# altera_avalon_timer register map
Registers are 16-bit, read-write, reset 0x0 unless marked. A register's access mark holds for its fields unless they carry their own. Offsets are from the block's base; lines under a group give offsets from that group; [hi:lo] are bit positions; {n}, {i} and the like mark numbered series; 'fields as' and 'values as' point back to an identical list; <NAME> marks a mode.

## Memory map
0x00000000 altera_avalon_timer size 0x10

## altera_avalon_timer
Base 0x00000000
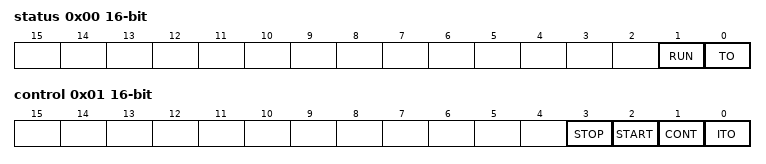
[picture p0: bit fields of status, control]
0x00 status — The status register has two defined bits. TO (timeout), RUN
  [1] RUN ro — The RUN bit reads as 1 when the internal counter is running; otherwise this bit reads as 0. The RUN bit is not changed by a write operation to the status register.
  [0] TO ro read-clears — The TO (timeout) bit is set to 1 when the internal counter reaches zero. Once set by a timeout event, the TO bit stays set until explicitly cleared by a master peripheral. Write zero to the status register to clear the TO bit.
0x01 control — The control register has four defined bits. ITO (Timeout Interrupt), CONT (continue), START, STOP
  [3] STOP wo — Writing a 1 to the STOP bit stops the internal counter. The STOP bit is an event bit that causes the counter to stop when a write operation is performed. If the timer is already stopped, writing a 1 to STOP has no effect. Writing a 0 to the stop bit has no effect. If the timer hardware is configured with Start/Stop control bits off, writing the STOP bit has no effect.
  [2] START wo — Writing a 1 to the START bit starts the internal counter running (counting down). The START bit is an event bit that enables the counter when a write operation is performed. If the timer is stopped, writing a 1 to the START bit causes the timer to restart counting from the number currently stored in its counter. If the timer is already running, writing a 1 to START has no effect. Writing 0 to the START bit has no effect.
  [1] CONT — The CONT (continuous) bit determines how the internal counter behaves when it reaches zero. If the CONT bit is 1, the counter runs continuously until it is stopped by the STOP bit. If CONT is 0, the counter stops after it reaches zero. When the counter reaches zero, it reloads with the value stored in the period registers, regardless of the CONT bit.
  [0] ITO — If the ITO bit is 1, the interval timer core generates an IRQ when the status register's TO bit is 1. When the ITO bit is 0, the timer does not generate IRQs.
0x02 ${period_name_0} reset not defined — The period_n registers together store the timeout period value when a write operation to one of the period_n register or the internal counter reaches 0. The timer's actual period is one cycle greater than the value stored in the period_n registers because the counter assumes the value zero for one clock cycle. Writing to one of the period_n registers stops the internal counter, except when the hardware is configured with Start/Stop control bits off. If Start/Stop control bits is off, writing either register does not stop the counter. When the hardware is configured with Writeable period disabled, writing to one of the period_n registers causes the counter to reset to the fixed Timeout Period specified at system generation time.
0x03 ${period_name_1} reset not defined
0x04 ${period_snap_0} reset not defined
0x05 ${period_snap_1} reset not defined
0x06 ${snap_0} — A master peripheral may request a coherent snapshot of the current internal counter by performing a write operation (write-data ignored) to one of the snap_n registers. When a write occurs, the value of the counter is copied to snap_n registers. The snapshot occurs whether or not the counter is running. Requesting a snapshot does not change the internal counter's operation.
0x07 ${snap_1}
0x08 ${snap_2}
0x09 ${snap_3}
